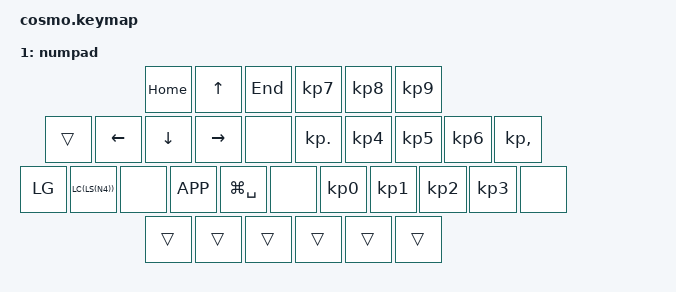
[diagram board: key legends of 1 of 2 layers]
// This file was generated from a template. Edit it to match your keyboard.
// See https://zmk.dev/docs/development/hardware-integration/new-shield for more instructions.

#include <behaviors.dtsi>
#include <dt-bindings/zmk/keys.h>

/ {
    // Define a default keymap here.
    // See https://zmk.dev/docs/development/hardware-integration/new-shield#default-keymap.
    behaviors {
      lt: layer_tap {
            flavor = "balanced";
            tapping-term-ms = <300>;
          };
      mt: mod_tap {
        quick-tap-ms = <450>;
          };
      tdy: tap_dance_y {
               compatible = "zmk,behavior-tap-dance";
               tapping-term-ms = <200>;
               #binding-cells = <0>;
               bindings = <&kp Y>, <&kp J>;
           };
      tdu: tap_dance_u {
               compatible = "zmk,behavior-tap-dance";
               tapping-term-ms = <200>;
               #binding-cells = <0>;
               bindings = <&kp U>, <&kp Q>;
           };
    };

    combos { 
        compatible = "zmk,combos";
        combo_a {
            key-positions = <7 8>;
            bindings = <&kp LPAR>;
            layers = <0>;
        };
        combo_b {
            key-positions = <7 8 9>;
            bindings = <&kp TAB>;
            layers = <0>;
        };
        combo_c {
            key-positions = <8 9>;
            bindings = <&kp PLUS>;
            require-prior-idle-ms = <50>;
            timeout-ms = <40>;
            layers = <0>;
        };
        combo_d {
            key-positions = <7 14>;
            bindings = <&kp SQT>;
            layers = <0>;
        };
        combo_e {
            key-positions = <8 13>;
            bindings = <&kp EQUAL>;
            layers = <0>;
        };
        combo_f {
            key-positions = <9 12>;
            bindings = <&kp DQT>;
            layers = <0>;
        };
        combo_g {
            key-positions = <12 13>;
            bindings = <&kp MINUS>;
            layers = <0>;
        };
        combo_h {
            key-positions = <13 14>;
            bindings = <&kp RPAR>;
            layers = <0>;
        };
        combo_i {
            key-positions = <14 15>;
            bindings = <&kp SLASH>;
            layers = <0>;
        };
    };

    keymap {
        compatible = "zmk,keymap";

        default_layer {
            display-name = "base";
            bindings = <
                &kp W &kp F &kp P   &kp L &tdu &tdy
                &lt 1 A  &kp R &kp S &kp T &kp G &kp M &kp N &kp E &kp I &kp O
                &kp Z &kp B &kp C &kp D &kp V &kp K &kp H &kp COMMA &kp DOT &kp X
                &mt LALT ESC &mt LSHIFT BSPC &mt LCTRL SPACE &mt LGUI RET
            >;
        };
        numpad_layer {
            display-name = "numpad";
            bindings = <
                &kp HOME &kp UP &kp END   &kp KP_N7 &kp KP_N8 &kp KP_N9
                &trans  &kp LEFT &kp DOWN &kp RIGHT &none &kp KP_DOT &kp KP_N4 &kp KP_N5 &kp KP_N6 &kp KP_COMMA
                &kp LG(LC(LS(N4))) &none &kp K_APP &kp LG(SPACE) &none &kp KP_N0 &kp KP_N1 &kp KP_N2 &kp KP_N3 &none
                &trans &trans &trans &trans &trans &trans
            >;
        };
    };
};
